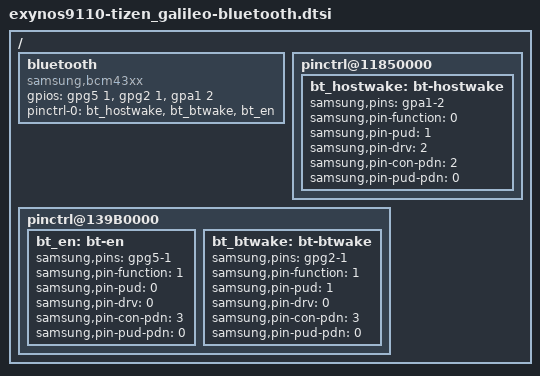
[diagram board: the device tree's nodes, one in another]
/* SAMSUNG UNIVERSAL9110 board device tree source
*
* Copyright (c) 2013 Samsung Electronics Co., Ltd.
*			   http://www.samsung.com
*
* This program is free software; you can redistribute it and/or modify
* it under the terms of the GNU General Public License version 2 as
* published by the Free Software Foundation.
*/

/ {
	bluetooth {
		compatible = "samsung,bcm43xx";

		gpios = <&gpg5 1 0	/*BT_EN*/
			 &gpg2 1 0x0    /*BT_WAKE*/
			 &gpa1 2 0x0    /*BT_HOST_WAKE*/ >;
		pinctrl-names = "default";
		pinctrl-0 = <&bt_hostwake &bt_btwake &bt_en>;
		status = "okay";
	};

	pinctrl@11850000 {
		bt_hostwake: bt-hostwake {
			samsung,pins = "gpa1-2";
			samsung,pin-function = <0>;
			samsung,pin-pud = <1>;
			samsung,pin-drv = <2>; /* default value is 2 */
			samsung,pin-con-pdn = <2>; /* default value is 2 */
			samsung,pin-pud-pdn = <0>; /* default value is 1 */
		};
	};

	pinctrl@139B0000 {
		bt_en: bt-en  {
			samsung,pins = "gpg5-1";
			samsung,pin-function = <1>;
			samsung,pin-pud = <0>;
			samsung,pin-drv = <0>;
			samsung,pin-con-pdn = <3>;
			samsung,pin-pud-pdn = <0>;
		};

		bt_btwake: bt-btwake {
			samsung,pins = "gpg2-1";
			samsung,pin-function = <1>;
			samsung,pin-pud = <1>;
			samsung,pin-drv = <0>;
			samsung,pin-con-pdn = <3>;
			samsung,pin-pud-pdn = <0>;
		};
	};
};
